# ATmega32U4 register map
File version: 1.0
Registers are 8-bit, read-write, reset 0x0 unless marked. A register's access mark holds for its fields unless they carry their own. Offsets are from the block's base; [hi:lo] are bit positions.

## TC0 — Timer/Counter, 8-bit
Base 0x00800000
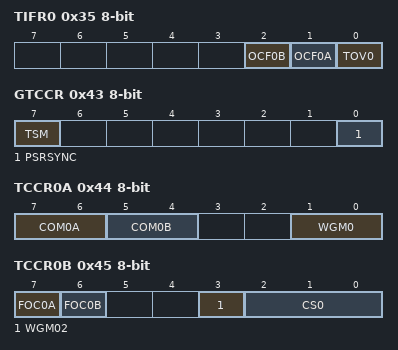
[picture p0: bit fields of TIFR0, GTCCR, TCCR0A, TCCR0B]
0x35 TIFR0 — Timer/Counter0 Interrupt Flag register
  [2] OCF0B — Timer/Counter0 Output Compare Flag 0B
  [1] OCF0A — Timer/Counter0 Output Compare Flag 0A
  [0] TOV0 — Timer/Counter0 Overflow Flag
0x43 GTCCR — General Timer/Counter Control Register
  [7] TSM — Timer/Counter Synchronization Mode
  [0] PSRSYNC — Prescaler Reset Timer/Counter1 and Timer/Counter0
0x44 TCCR0A — Timer/Counter Control Register A
  [7:6] COM0A — Compare Output Mode, Phase Correct PWM Mode
  [5:4] COM0B — Compare Output Mode, Fast PWm
  [1:0] WGM0 — Waveform Generation Mode
0x45 TCCR0B — Timer/Counter Control Register B
  [7] FOC0A — Force Output Compare A
  [6] FOC0B — Force Output Compare B
  [3] WGM02
  [2:0] CS0 — Clock Select
0x46 TCNT0 — Timer/Counter0
0x47 OCR0A — Timer/Counter0 Output Compare Register
0x48 OCR0B — Timer/Counter0 Output Compare Register

## TC0_2 — Timer/Counter, 8-bit
Base 0x00800000
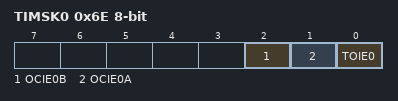
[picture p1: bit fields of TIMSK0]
0x6E TIMSK0 — Timer/Counter0 Interrupt Mask Register
  [2] OCIE0B — Timer/Counter0 Output Compare Match B Interrupt Enable
  [1] OCIE0A — Timer/Counter0 Output Compare Match A Interrupt Enable
  [0] TOIE0 — Timer/Counter0 Overflow Interrupt Enable

## TC1 — Timer/Counter, 16-bit
Base 0x00800000
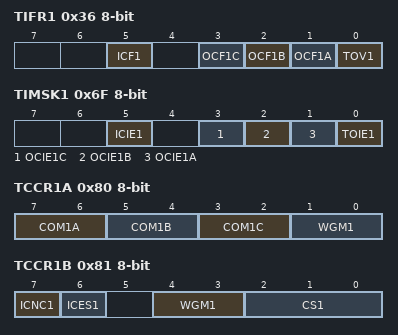
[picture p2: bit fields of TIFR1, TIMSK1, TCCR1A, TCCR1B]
0x36 TIFR1 — Timer/Counter1 Interrupt Flag register
  [5] ICF1 — Input Capture Flag 1
  [3] OCF1C — Output Compare Flag 1C
  [2] OCF1B — Output Compare Flag 1B
  [1] OCF1A — Output Compare Flag 1A
  [0] TOV1 — Timer/Counter1 Overflow Flag
0x6F TIMSK1 — Timer/Counter1 Interrupt Mask Register
  [5] ICIE1 — Timer/Counter1 Input Capture Interrupt Enable
  [3] OCIE1C — Timer/Counter1 Output Compare C Match Interrupt Enable
  [2] OCIE1B — Timer/Counter1 Output Compare B Match Interrupt Enable
  [1] OCIE1A — Timer/Counter1 Output Compare A Match Interrupt Enable
  [0] TOIE1 — Timer/Counter1 Overflow Interrupt Enable
0x80 TCCR1A — Timer/Counter1 Control Register A
  [7:6] COM1A — Compare Output Mode 1A, bits
  [5:4] COM1B — Compare Output Mode 1B, bits
  [3:2] COM1C — Compare Output Mode 1C, bits
  [1:0] WGM1 — Waveform Generation Mode
0x81 TCCR1B — Timer/Counter1 Control Register B
  [7] ICNC1 — Input Capture 1 Noise Canceler
  [6] ICES1 — Input Capture 1 Edge Select
  [4:3] WGM1 — Waveform Generation Mode
  [2:0] CS1 — Prescaler source of Timer/Counter 1
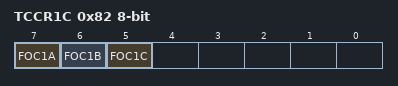
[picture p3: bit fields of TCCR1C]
0x82 TCCR1C — Timer/Counter 1 Control Register C
  [7] FOC1A — Force Output Compare 1A
  [6] FOC1B — Force Output Compare 1B
  [5] FOC1C — Force Output Compare 1C
0x84 TCNT1 16-bit (reset mask 0xFF) — Timer/Counter1 Bytes
0x86 ICR1 16-bit (reset mask 0xFF) — Timer/Counter1 Input Capture Register Bytes
0x88 OCR1A 16-bit (reset mask 0xFF) — Timer/Counter1 Output Compare Register A Bytes
0x8A OCR1B 16-bit (reset mask 0xFF) — Timer/Counter1 Output Compare Register B Bytes
0x8C OCR1C 16-bit (reset mask 0xFF) — Timer/Counter1 Output Compare Register C Bytes

## TC3 — Timer/Counter, 16-bit
Base 0x00800000
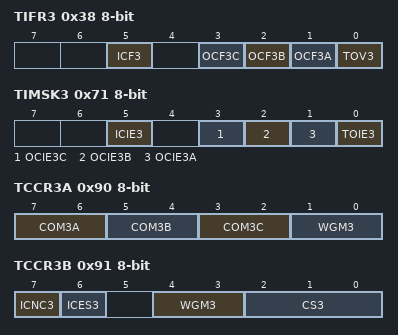
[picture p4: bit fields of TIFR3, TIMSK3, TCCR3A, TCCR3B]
0x38 TIFR3 — Timer/Counter3 Interrupt Flag register
  [5] ICF3 — Input Capture Flag 3
  [3] OCF3C — Output Compare Flag 3C
  [2] OCF3B — Output Compare Flag 3B
  [1] OCF3A — Output Compare Flag 3A
  [0] TOV3 — Timer/Counter3 Overflow Flag
0x71 TIMSK3 — Timer/Counter3 Interrupt Mask Register
  [5] ICIE3 — Timer/Counter3 Input Capture Interrupt Enable
  [3] OCIE3C — Timer/Counter3 Output Compare C Match Interrupt Enable
  [2] OCIE3B — Timer/Counter3 Output Compare B Match Interrupt Enable
  [1] OCIE3A — Timer/Counter3 Output Compare A Match Interrupt Enable
  [0] TOIE3 — Timer/Counter3 Overflow Interrupt Enable
0x90 TCCR3A — Timer/Counter3 Control Register A
  [7:6] COM3A — Compare Output Mode 1A, bits
  [5:4] COM3B — Compare Output Mode 3B, bits
  [3:2] COM3C — Compare Output Mode 3C, bits
  [1:0] WGM3 — Waveform Generation Mode
0x91 TCCR3B — Timer/Counter3 Control Register B
  [7] ICNC3 — Input Capture 3 Noise Canceler
  [6] ICES3 — Input Capture 3 Edge Select
  [4:3] WGM3 — Waveform Generation Mode
  [2:0] CS3 — Prescaler source of Timer/Counter 3
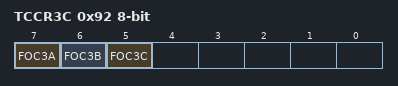
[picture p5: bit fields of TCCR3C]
0x92 TCCR3C — Timer/Counter 3 Control Register C
  [7] FOC3A — Force Output Compare 3A
  [6] FOC3B — Force Output Compare 3B
  [5] FOC3C — Force Output Compare 3C
0x94 TCNT3 16-bit (reset mask 0xFF) — Timer/Counter3 Bytes
0x96 ICR3 16-bit (reset mask 0xFF) — Timer/Counter3 Input Capture Register Bytes
0x98 OCR3A 16-bit (reset mask 0xFF) — Timer/Counter3 Output Compare Register A Bytes
0x9A OCR3B 16-bit (reset mask 0xFF) — Timer/Counter3 Output Compare Register B Bytes
0x9C OCR3C 16-bit (reset mask 0xFF) — Timer/Counter3 Output Compare Register B Bytes
